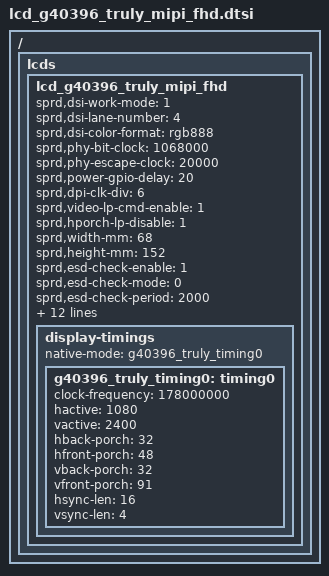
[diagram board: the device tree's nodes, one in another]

/*
 * G40396  LCD config dtsi file for spreadtrum
 *
 * Copyright (C) 2018, Spreadtrum Communications Inc.
 *
 * SPDX-License-Identifier: (GPL-2.0+ OR MIT)
 */

/ {
	fragment {
		target-path = "/";
		__overlay__ {
			lcds {
				lcd_g40396_truly_mipi_fhd: lcd_g40396_truly_mipi_fhd {

					sprd,dsi-work-mode = <1>; /* video burst mode*/
					sprd,dsi-lane-number = <4>;
					sprd,dsi-color-format = "rgb888";

					sprd,phy-bit-clock = <1068000>;	/* kbps */
					sprd,phy-escape-clock = <20000>;/* kHz */

					sprd,power-gpio-delay = <20>;/* ms */
					sprd,dpi-clk-div = <6>;
					sprd,video-lp-cmd-enable = <1>;
					sprd,hporch-lp-disable = <1>;

					sprd,width-mm = <68>;
					sprd,height-mm = <152>;

					sprd,esd-check-enable = <1>;
					sprd,esd-check-mode = <0>;
					sprd,esd-check-period = <2000>;
					sprd,esd-check-regs = <0xA>;
					sprd,esd-return-code = <0x9c>;

					sprd,reset-on-sequence = <1 5>, <0 5>, <1 20>;
					sprd,reset-off-sequence = <0 5>;

					sprd,video-lp-en-mode = <15>;

					sprd,use-dcs-write;
					sprd,initial-command = [
						//CMD2 ENABLE
						29 00 00 02 00 00
						29 00 00 04 FF 87 56 01
						29 00 00 02 00 80
						29 00 00 03 FF 87 56
						//Panel resulotion
						29 00 00 02 00 A1
						29 00 00 07 B3 04 38 09 60 00 FC
						29 00 00 02 00 80
						29 00 00 07 C0 00 8C 00 20 00 08
						29 00 00 02 00 90
						29 00 00 07 C0 00 8C 00 20 00 08
						29 00 00 02 00 A0
						29 00 00 07 C0 01 19 00 20 00 08
						29 00 00 02 00 B0
						29 00 00 06 C0 00 8C 00 20 08
						29 00 00 02 00 C1
						29 00 00 09 C0 00 D0 00 9F 00 8B 00 EE
						29 00 00 02 00 D7
						29 00 00 07 C0 00 8B 00 20 00 08
						29 00 00 02 00 A3
						29 00 00 07 C1 00 3E 00 3E 00 02
						29 00 00 02 00 80
						29 00 00 11 CE 01 81 09 13 00 D0 00 E8 00 82 00 9A 00 68 00 74
						29 00 00 02 00 90
						29 00 00 10 CE 00 8E 0C DF 00 8E 80 09 13 00 04 00 08 08 08
						29 00 00 02 00 A0
						29 00 00 04 CE 00 00 00
						29 00 00 02 00 B0
						29 00 00 04 CE 22 00 00
						29 00 00 02 00 D1
						29 00 00 08 CE 00 00 01 00 00 00 00
						29 00 00 02 00 E1
						29 00 00 0C CE 08 02 4D 02 4D 02 4D 00 00 00 00
						29 00 00 02 00 F1
						29 00 00 0A CE 13 09 0D 00 F6 01 96 00 C2
						29 00 00 02 00 B0
						29 00 00 05 CF 00 00 68 6C
						29 00 00 02 00 B5
						29 00 00 05 CF 04 04 E4 E8
						29 00 00 02 00 C0
						29 00 00 05 CF 09 09 2C 30
						29 00 00 02 00 C5
						29 00 00 05 CF 00 00 08 0C
						29 00 00 02 00 E8
						29 00 00 02 C0 40
						29 00 00 02 00 80
						29 00 00 05 C2 84 01 3F 3F
						29 00 00 02 00 90
						29 00 00 05 C2 02 01 00 00
						29 00 00 02 00 A0
						29 00 00 10 C2 84 04 00 00 8A 83 04 00 00 8A 82 04 00 00 8A
						29 00 00 02 00 B0
						29 00 00 06 C2 81 04 00 00 8A
						29 00 00 02 00 E0
						29 00 00 0F C2 33 33 33 33 33 33 00 00 12 00 05 02 00 00
						29 00 00 02 00 C0
						29 00 00 05 C3 99 99 99 99
						29 00 00 02 00 D0
						29 00 00 0D C3 45 00 00 05 45 00 00 05 45 00 00 05
						29 00 00 02 00 80
						29 00 00 11 CB C1 C1 00 C1 C1 00 00 C1 FE 01 C1 00 FD C1 00 C0
						29 00 00 02 00 90
						29 00 00 11 CB C0 00 00 00 00 00 00 00 FF 00 00 00 00 00 00 00
						29 00 00 02 00 A0
						29 00 00 05 CB 00 00 00 00
						29 00 00 02 00 B0
						29 00 00 05 CB 55 55 95 55
						29 00 00 02 00 C0
						29 00 00 05 CB 10 51 94 50
						29 00 00 02 00 80
						29 00 00 11 CC 00 00 00 25 25 29 16 17 18 19 1A 1B 22 24 06 06
						29 00 00 02 00 90
						29 00 00 09 CC 08 08 24 02 12 01 29 29
						29 00 00 02 00 80
						29 00 00 11 CD 00 00 00 25 25 29 16 17 18 19 1A 1B 22 24 07 07
						29 00 00 02 00 90
						29 00 00 09 CD 09 09 24 02 12 01 29 29
						29 00 00 02 00 A0
						29 00 00 11 CC 00 00 00 25 25 29 16 17 18 19 1A 1B 24 23 09 09
						29 00 00 02 00 B0
						29 00 00 09 CC 07 07 24 12 02 01 29 29
						29 00 00 02 00 A0
						29 00 00 11 CD 00 00 00 25 25 29 16 17 18 19 1A 1B 24 23 08 08
						29 00 00 02 00 B0
						29 00 00 09 CD 06 06 24 12 02 01 29 29
						29 00 00 02 00 80
						29 00 00 02 A7 10
						29 00 00 02 00 82
						29 00 00 03 A7 33 02
						29 00 00 02 00 85
						29 00 00 02 A7 10
						//Reduce Source ring for COB
						29 00 00 02 00 85
						29 00 00 02 C4 1C
						29 00 00 02 00 97
						29 00 00 02 C4 01
						//Source remapping
						29 00 00 02 00 A0
						29 00 00 04 C4 2D D2 2D
						//VGH N_pump x2 (VGH=9.6V)
						29 00 00 02 00 93
						29 00 00 02 C5 29
						//VGH I_pump x2 (VGH=9.6V)
						29 00 00 02 00 97
						29 00 00 02 C5 29
						//VGL N_pump x2 (VGL=-9V)
						29 00 00 02 00 9A
						29 00 00 02 C5 23
						//VGL I_pump x2 (VGL=-9V)
						29 00 00 02 00 9C
						29 00 00 02 C5 23
						//VGHO1 (VGHO1=8.6V)
						29 00 00 02 00 B6
						29 00 00 03 C5 1F 1F
						//VGLO1 (VGLO1=-8V)
						29 00 00 02 00 B8
						29 00 00 03 C5 19 19
						29 00 00 02 00 9B
						29 00 00 02 F5 4B
						29 00 00 02 00 93
						29 00 00 03 F5 00 00
						29 00 00 02 00 9D
						29 00 00 02 F5 49
						29 00 00 02 00 82
						29 00 00 03 F5 00 00
						29 00 00 02 00 8C
						29 00 00 04 C3 00 00 00
						29 00 00 02 00 84
						29 00 00 03 C5 28 28
						29 00 00 02 00 A4
						29 00 00 02 D7 00
						29 00 00 02 00 80
						29 00 00 03 F5 59 59
						29 00 00 02 00 84
						29 00 00 04 F5 59 59 59
						29 00 00 02 00 96
						29 00 00 02 F5 59
						29 00 00 02 00 A6
						29 00 00 02 F5 59
						29 00 00 02 00 CA
						29 00 00 02 C0 80
						29 00 00 02 00 B1
						29 00 00 02 F5 1F
						//GVDDP/N=+/-5.2V
						29 00 00 02 00 00
						29 00 00 03 D8 2F 2F
						//VCOM=-0.2V
						29 00 00 02 00 00
						29 00 00 03 D9 23 23
						29 00 00 02 00 86   //Normal
						29 00 00 07 C0 01 04 01 04 0E 03
						29 00 00 02 00 96   //Idle
						29 00 00 07 C0 01 04 01 04 0D 03
						29 00 00 02 00 A6   //LPF
						29 00 00 07 C0 01 04 01 04 18 03
						29 00 00 02 00 E9   //Scaling
						29 00 00 07 C0 01 04 01 04 0D 03
						29 00 00 02 00 A3   //pre_dmy
						29 00 00 07 CE 01 04 01 04 0D 03
						29 00 00 02 00 B3   //pos_dmy
						29 00 00 07 CE 01 04 01 04 0D 03
						//Gamma value0103
						29 00 00 02 00 A0
						29 00 00 02 D7 04
						29 00 00 02 00 00
						29 00 00 29 E1 00 04 08 0F 1A 1A 22 28 33 5C 3B 42 48 4D 1B 53 5B 63 6A 2B 72 79 81 8A 3A 95 9B A1 A9 0A B2 BD CB D4 6B E0 EE FA FF 17
						29 00 00 02 00 00
						29 00 00 29 E2 00 04 08 0F 1A 1A 22 28 33 5C 3B 42 48 4E 18 53 5B 63 6B 28 72 79 81 8A 2A 94 9B A1 A9 CA B2 BD CB D5 68 E0 EE FA FF 67
						29 00 00 02 00 00
						29 00 00 29 E3 00 03 07 0E 3F 19 21 27 31 46 39 40 47 4C B2 51 5A 61 69 8D 70 77 7F 88 68 92 97 9D A5 2C AD B7 C3 CB 58 D4 DF E6 EA 7B
						29 00 00 02 00 00
						29 00 00 29 E4 00 03 07 0E 3F 19 21 27 31 45 39 40 47 4C B1 51 59 61 69 BD 70 77 7F 87 67 91 97 9D A5 EC AD B7 C3 CB 49 D4 E0 E6 EA 4B
						29 00 00 02 00 00
						29 00 00 29 E5 00 03 08 0E 33 19 20 27 31 31 39 41 47 4C 87 51 5A 62 69 D6 70 77 7F 88 B8 92 97 9E A5 32 AE B8 C5 CE 2C D8 E6 F0 F5 F6
						29 00 00 02 00 00
						29 00 00 29 E6 00 03 08 0E 33 19 20 27 31 31 39 41 47 4C 87 51 5A 62 69 D2 70 77 7F 88 B8 92 97 9E A5 32 AE B8 C5 CE 2D D9 E7 F0 F5 06
						29 00 00 02 00 CC
						29 00 00 02 C0 10
						29 00 00 02 00 00
						29 00 00 04 FF FF FF FF
						15 00 00 02 35 00
						15 00 00 02 51 FF
						15 00 00 02 53 24
						15 00 00 02 55 00
						//----------------------LCD initial code End----------------------//
						//SLPOUT and DISPON
						05 b4 00 01 11
						05 64 00 01 29
						];

					sprd,sleep-in-command = [
						15 00 00 02 00 00
						39 00 00 04 FF 87 56 01
						15 00 00 02 00 80
						39 00 00 03 FF 87 56
						05 00 00 01 28
						05 78 00 01 10
						15 00 00 02 00 00
						39 00 00 05 F7 5A A5 95 27
						];

					sprd,sleep-out-command = [
						05 78 00 01 11
						05 00 00 01 29
						];

					display-timings {
						native-mode = <&g40396_truly_timing0>;

						g40396_truly_timing0: timing0 {
							clock-frequency = <178000000>;
							hactive = <1080>;
							vactive = <2400>;
							hback-porch = <32>;
							hfront-porch = <48>;
							vback-porch = <32>;
							vfront-porch = <91>;
							hsync-len = <16>;
							vsync-len = <4>;
						};
					};
				};
			};
		};
	};
};
